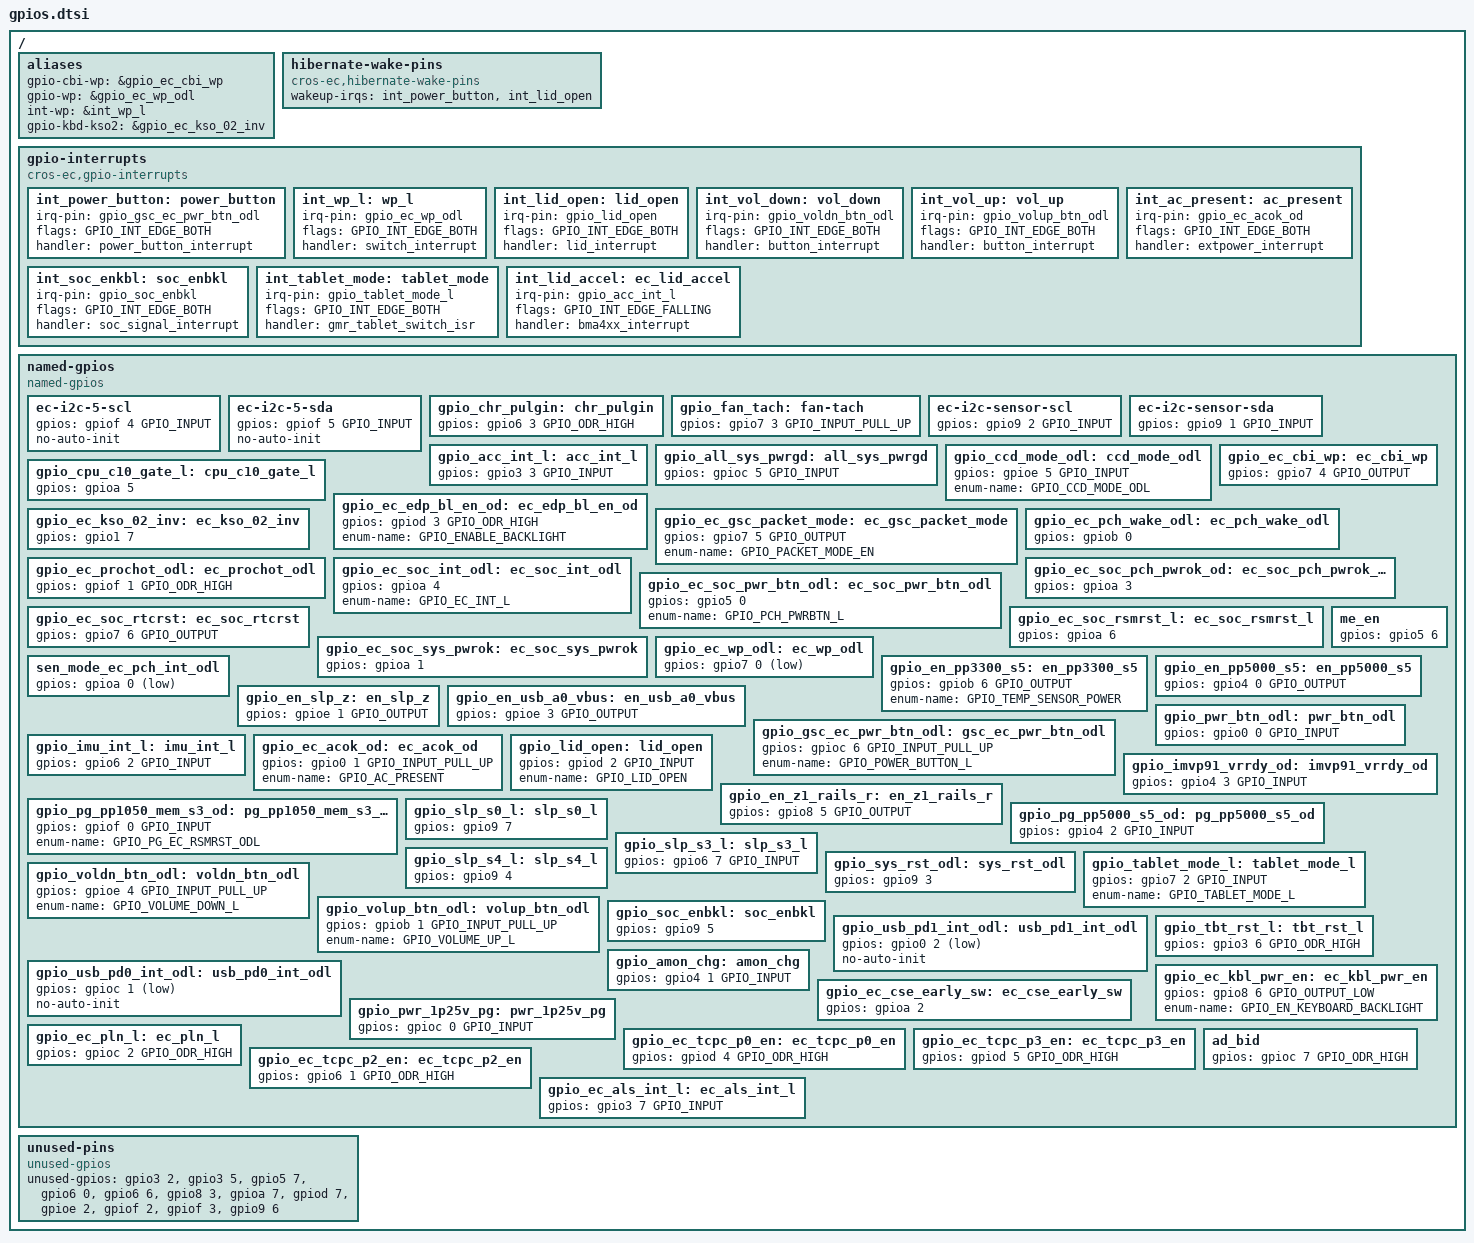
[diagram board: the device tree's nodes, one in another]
/* Copyright 2024 The ChromiumOS Authors
 * Use of this source code is governed by a BSD-style license that can be
 * found in the LICENSE file.
 */

/ {
	aliases {
		gpio-cbi-wp = &gpio_ec_cbi_wp;
		gpio-wp = &gpio_ec_wp_odl;
		int-wp = &int_wp_l;
		gpio-kbd-kso2 = &gpio_ec_kso_02_inv;
	};

	hibernate-wake-pins {
		compatible = "cros-ec,hibernate-wake-pins";
		wakeup-irqs = <
			&int_power_button
			&int_lid_open
		>;
	};

	gpio-interrupts {
		compatible = "cros-ec,gpio-interrupts";

		int_power_button: power_button {
			irq-pin = <&gpio_gsc_ec_pwr_btn_odl>;
			flags = <GPIO_INT_EDGE_BOTH>;
			handler = "power_button_interrupt";
		};
		int_wp_l: wp_l {
			irq-pin = <&gpio_ec_wp_odl>;
			flags = <GPIO_INT_EDGE_BOTH>;
			handler = "switch_interrupt";
		};
		int_lid_open: lid_open {
			irq-pin = <&gpio_lid_open>;
			flags = <GPIO_INT_EDGE_BOTH>;
			handler = "lid_interrupt";
		};
		int_vol_down: vol_down {
			irq-pin = <&gpio_voldn_btn_odl>;
			flags = <GPIO_INT_EDGE_BOTH>;
			handler = "button_interrupt";
		};
		int_vol_up: vol_up {
			irq-pin = <&gpio_volup_btn_odl>;
			flags = <GPIO_INT_EDGE_BOTH>;
			handler = "button_interrupt";
		};
		int_ac_present: ac_present {
			irq-pin = <&gpio_ec_acok_od>;
			flags = <GPIO_INT_EDGE_BOTH>;
			handler = "extpower_interrupt";
		};
		int_soc_enkbl: soc_enbkl {
			irq-pin = <&gpio_soc_enbkl>;
			flags = <GPIO_INT_EDGE_BOTH>;
			handler = "soc_signal_interrupt";
		};
		int_tablet_mode: tablet_mode {
			irq-pin = <&gpio_tablet_mode_l>;
			flags = <GPIO_INT_EDGE_BOTH>;
			handler = "gmr_tablet_switch_isr";
		};
		int_lid_accel: ec_lid_accel  {
			irq-pin = <&gpio_acc_int_l>;
			flags = <GPIO_INT_EDGE_FALLING>;
			handler = "bma4xx_interrupt";
		};
	};

	named-gpios {
		compatible = "named-gpios";
		ec-i2c-5-scl {
			gpios = <&gpiof 4 GPIO_INPUT>;
			no-auto-init;
		};
		ec-i2c-5-sda {
			gpios = <&gpiof 5 GPIO_INPUT>;
			no-auto-init;
		};
		gpio_chr_pulgin: chr_pulgin {
			gpios = <&gpio6 3 GPIO_ODR_HIGH>;
		};
		gpio_fan_tach: fan-tach {
			gpios = <&gpio7 3 GPIO_INPUT_PULL_UP>;
		};
		ec-i2c-sensor-scl {
			gpios = <&gpio9 2 GPIO_INPUT>;
		};
		ec-i2c-sensor-sda {
			gpios = <&gpio9 1 GPIO_INPUT>;
		};
		gpio_acc_int_l: acc_int_l {
			gpios = <&gpio3 3 GPIO_INPUT>;
		};
		gpio_all_sys_pwrgd: all_sys_pwrgd {
			gpios = <&gpioc 5 GPIO_INPUT>;
		};
		gpio_ccd_mode_odl: ccd_mode_odl {
			gpios = <&gpioe 5 GPIO_INPUT>;
			enum-name = "GPIO_CCD_MODE_ODL";
		};
		gpio_cpu_c10_gate_l: cpu_c10_gate_l {
			gpios = <&gpioa 5 (GPIO_INPUT | GPIO_VOLTAGE_1P8)>;
		};
		gpio_ec_cbi_wp: ec_cbi_wp {
			gpios = <&gpio7 4 GPIO_OUTPUT>;
		};
		gpio_ec_edp_bl_en_od: ec_edp_bl_en_od {
			gpios = <&gpiod 3 GPIO_ODR_HIGH>;
			enum-name = "GPIO_ENABLE_BACKLIGHT";
		};
		gpio_ec_gsc_packet_mode: ec_gsc_packet_mode {
			gpios = <&gpio7 5 GPIO_OUTPUT>;
			enum-name = "GPIO_PACKET_MODE_EN";
		};
		gpio_ec_kso_02_inv: ec_kso_02_inv {
			gpios = <&gpio1 7 (GPIO_OUTPUT | GPIO_ACTIVE_HIGH)>;
		};
		gpio_ec_pch_wake_odl: ec_pch_wake_odl {
			gpios = <&gpiob 0 (GPIO_ODR_LOW | GPIO_VOLTAGE_1P8)>;
		};
		gpio_ec_prochot_odl: ec_prochot_odl {
			gpios = <&gpiof 1 GPIO_ODR_HIGH>;
		};
		gpio_ec_soc_int_odl: ec_soc_int_odl {
			gpios = <&gpioa 4 (GPIO_OUTPUT | GPIO_VOLTAGE_1P8)>;
			enum-name = "GPIO_EC_INT_L";
		};
		gpio_ec_soc_pch_pwrok_od: ec_soc_pch_pwrok_od {
			gpios = <&gpioa 3 (GPIO_OUTPUT | GPIO_VOLTAGE_1P8)>;
		};
		gpio_ec_soc_pwr_btn_odl: ec_soc_pwr_btn_odl {
			gpios = <&gpio5 0 (GPIO_ODR_HIGH | GPIO_VOLTAGE_1P8)>;
			enum-name = "GPIO_PCH_PWRBTN_L";
		};
		gpio_ec_soc_rsmrst_l: ec_soc_rsmrst_l {
			gpios = <&gpioa 6 (GPIO_OUTPUT | GPIO_VOLTAGE_1P8)>;
		};
		gpio_ec_soc_rtcrst: ec_soc_rtcrst {
			gpios = <&gpio7 6 GPIO_OUTPUT>;
		};
		gpio_ec_soc_sys_pwrok: ec_soc_sys_pwrok {
			gpios = <&gpioa 1 (GPIO_OUTPUT | GPIO_VOLTAGE_1P8)>;
		};
		/delete-node/ write-protect;
		gpio_ec_wp_odl: ec_wp_odl {
			gpios = <&gpio7 0 (GPIO_INPUT | GPIO_ACTIVE_LOW)>;
		};
		sen_mode_ec_pch_int_odl {
			gpios = <&gpioa 0 (GPIO_ODR_HIGH | GPIO_ACTIVE_LOW | GPIO_VOLTAGE_1P8)>;
		};
		gpio_en_pp3300_s5: en_pp3300_s5 {
			gpios = <&gpiob 6 GPIO_OUTPUT>;
			enum-name = "GPIO_TEMP_SENSOR_POWER";
		};
		me_en {
			/* workaround for b/333336079, reserved */
			gpios = <&gpio5 6 (GPIO_INPUT | GPIO_VOLTAGE_1P8)>;
		};
		gpio_en_pp5000_s5: en_pp5000_s5 {
			gpios = <&gpio4 0 GPIO_OUTPUT>;
		};
		gpio_en_slp_z: en_slp_z {
			gpios = <&gpioe 1 GPIO_OUTPUT>;
		};
		gpio_en_usb_a0_vbus: en_usb_a0_vbus {
			gpios = <&gpioe 3 GPIO_OUTPUT>;
		};
		gpio_gsc_ec_pwr_btn_odl: gsc_ec_pwr_btn_odl {
			gpios = <&gpioc 6 GPIO_INPUT_PULL_UP>;
			enum-name = "GPIO_POWER_BUTTON_L";
		};
		gpio_pwr_btn_odl: pwr_btn_odl {
			gpios = <&gpio0 0 GPIO_INPUT>;
		};
		gpio_imu_int_l: imu_int_l {
			gpios = <&gpio6 2 GPIO_INPUT>;
		};
		gpio_ec_acok_od: ec_acok_od {
			gpios = <&gpio0 1 GPIO_INPUT_PULL_UP>;
			enum-name = "GPIO_AC_PRESENT";
		};
		gpio_imvp91_vrrdy_od: imvp91_vrrdy_od {
			gpios = <&gpio4 3 GPIO_INPUT>;
		};
		gpio_lid_open: lid_open {
			gpios = <&gpiod 2 GPIO_INPUT>;
			enum-name = "GPIO_LID_OPEN";
		};
		gpio_en_z1_rails_r: en_z1_rails_r {
			gpios = <&gpio8 5 GPIO_OUTPUT>;
		};
		gpio_pg_pp1050_mem_s3_od: pg_pp1050_mem_s3_od {
			gpios = <&gpiof 0 GPIO_INPUT>;
			enum-name = "GPIO_PG_EC_RSMRST_ODL";
		};
		gpio_pg_pp5000_s5_od: pg_pp5000_s5_od {
			gpios = <&gpio4 2 GPIO_INPUT>;
		};
		gpio_slp_s0_l: slp_s0_l {
			gpios = <&gpio9 7 (GPIO_INPUT | GPIO_VOLTAGE_1P8)>;
		};
		gpio_slp_s3_l: slp_s3_l {
			gpios = <&gpio6 7 GPIO_INPUT>;
		};
		gpio_slp_s4_l: slp_s4_l {
			gpios = <&gpio9 4 (GPIO_INPUT | GPIO_VOLTAGE_1P8)>;
		};
		gpio_sys_rst_odl: sys_rst_odl {
			gpios = <&gpio9 3 (GPIO_ODR_HIGH | GPIO_VOLTAGE_1P8)>;
		};
		gpio_tablet_mode_l: tablet_mode_l {
			gpios = <&gpio7 2 GPIO_INPUT>;
			enum-name = "GPIO_TABLET_MODE_L";
		};
		gpio_voldn_btn_odl: voldn_btn_odl {
			gpios = <&gpioe 4 GPIO_INPUT_PULL_UP>;
			enum-name = "GPIO_VOLUME_DOWN_L";
		};
		gpio_volup_btn_odl: volup_btn_odl {
			gpios = <&gpiob 1 GPIO_INPUT_PULL_UP>;
			enum-name = "GPIO_VOLUME_UP_L";
		};
		gpio_soc_enbkl: soc_enbkl {
			gpios = <&gpio9 5 (GPIO_INPUT | GPIO_VOLTAGE_1P8)>;
		};
		gpio_usb_pd1_int_odl: usb_pd1_int_odl {
			gpios = <&gpio0 2 (GPIO_INPUT | GPIO_ACTIVE_LOW)>;
		};
		gpio_usb_pd0_int_odl: usb_pd0_int_odl {
			gpios = <&gpioc 1 (GPIO_INPUT | GPIO_ACTIVE_LOW)>;
		};
		gpio_tbt_rst_l: tbt_rst_l {
			gpios = <&gpio3 6 GPIO_ODR_HIGH>;
		};
		gpio_amon_chg: amon_chg {
			gpios = <&gpio4 1 GPIO_INPUT>;
		};
		gpio_ec_kbl_pwr_en: ec_kbl_pwr_en {
			gpios = <&gpio8 6 GPIO_OUTPUT_LOW>;
			enum-name = "GPIO_EN_KEYBOARD_BACKLIGHT";
		};
		gpio_ec_cse_early_sw: ec_cse_early_sw {
			gpios = <&gpioa 2 (GPIO_OUTPUT | GPIO_VOLTAGE_1P8)>;
		};
		gpio_pwr_1p25v_pg: pwr_1p25v_pg {
			gpios = <&gpioc 0 GPIO_INPUT>;
		};
		gpio_ec_pln_l: ec_pln_l {
			gpios = <&gpioc 2 GPIO_ODR_HIGH>;
		};
		gpio_ec_tcpc_p0_en: ec_tcpc_p0_en {
			gpios = <&gpiod 4 GPIO_ODR_HIGH>;
		};
		gpio_ec_tcpc_p3_en: ec_tcpc_p3_en {
			gpios = <&gpiod 5 GPIO_ODR_HIGH>;
		};
		gpio_ec_tcpc_p2_en: ec_tcpc_p2_en {
			gpios = <&gpio6 1 GPIO_ODR_HIGH>;
		};
		gpio_ec_als_int_l: ec_als_int_l {
			gpios =  <&gpio3 7 GPIO_INPUT>;
		};
		ad_bid {
			gpios = <&gpioc 7 GPIO_ODR_HIGH>;
		};
	};

	/*
	 * Declare unused GPIOs so that they are shut down
	 * and use minimal power
	 */
	unused-pins {
		compatible = "unused-gpios";
		unused-gpios =
			<&gpio3 2 0>,
			<&gpio3 5 0>,
			<&gpio5 7 0>,
			<&gpio6 0 0>,
			<&gpio6 6 0>,
			<&gpio8 3 0>,
			<&gpioa 7 0>,
			<&gpiod 7 0>,
			<&gpioe 2 0>,
			<&gpiof 2 0>,
			<&gpiof 3 0>,
			<&gpio9 6 0>;
	};
};

/* These GPIOS are initialized by the PDC driver */
&gpio_usb_pd0_int_odl {
	no-auto-init;
};

&gpio_usb_pd1_int_odl {
	no-auto-init;
};

